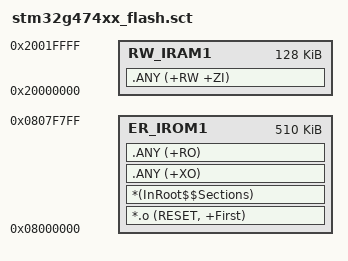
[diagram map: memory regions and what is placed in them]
; *********************************************************************************
; *** Scatter-Loading Description File generated by STM32CubeMX/LinkerGenerator ***
; *********************************************************************************;

LR_IROM1 0x8000000 0x0007F800  {  ; 为最后一个 2 KB 参数页保留空间
  ER_IROM1 0x8000000 0x0007F800  {  ; 应用程序代码最大不超过参数页起始地址
   *.o (RESET, +First)
   *(InRoot$$Sections)
   .ANY (+XO)
   .ANY (+RO)
  }
  RW_IRAM1 0x20000000 0x00020000  {  ; load address = excetion address
   .ANY (+RW +ZI)
  }
;***region***;
;***endregion***;
}


/*-Start of  regions- Auto-generated By STM32CubeMX-*/
